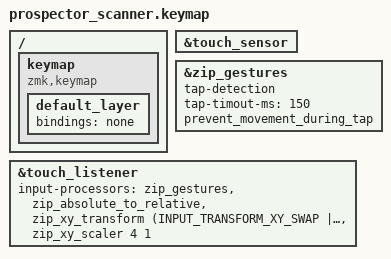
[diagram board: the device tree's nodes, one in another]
/*
 * Copyright (c) 2024 The ZMK Contributors
 *
 * SPDX-License-Identifier: MIT
 */

#include <behaviors.dtsi>
#include <dt-bindings/zmk/keys.h>

#include <input/processors.dtsi>
#include <dt-bindings/zmk/input_transform.h>
#include <zephyr/dt-bindings/input/input-event-codes.h>

#include <behaviors/input_processor_gestures.dtsi>
#include <behaviors/input_processor_absolute_to_relative.dtsi>
#include <behaviors/input_processor_gestures.dtsi>

// Alias &touch_sensor to &glidepoint for input gestures module
glidepoint: &touch_sensor {};

&zip_gestures {
    tap-detection;
    tap-timout-ms = <150>;
    prevent_movement_during_tap;
};

&touch_listener {
    input-processors = <
        &zip_gestures
        &zip_absolute_to_relative
        &zip_xy_transform (INPUT_TRANSFORM_XY_SWAP | INPUT_TRANSFORM_Y_INVERT)
        &zip_xy_scaler 4 1
    >;
};

/ {
    keymap {
        compatible = "zmk,keymap";

        default_layer {
            // Scanner device with minimal input - use none for display-only device
            bindings = <
                &none  // No key action needed for scanner
            >;
        };
    };
};
